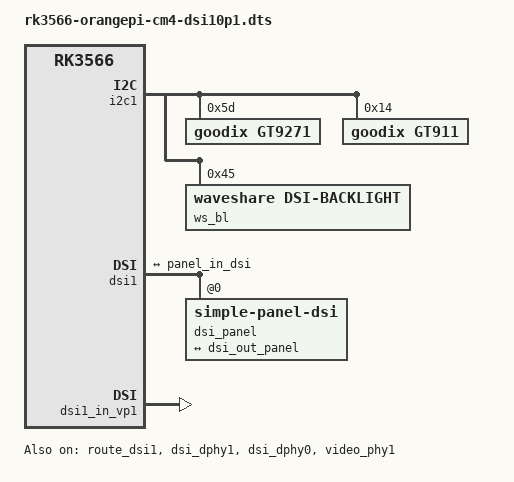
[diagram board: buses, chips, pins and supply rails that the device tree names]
// SPDX-License-Identifier: (GPL-2.0+ OR MIT)
/*
* Copyright (c) 2020 Rockchip Electronics Co., Ltd.
*
*/
/dts-v1/;

#include "rk3566-orangepi-cm4.dtsi"

&i2c1 {
    gt9271: gt9271@5d {
		status = "okay";
		compatible = "goodix,gt9271";
		reg = <0x5d>;
		pinctrl-names = "default";
	};

    gt911: gt911@14 {
		status = "okay";
		compatible = "goodix,gt911";
		reg = <0x14>;
    };

	ws_bl: ws-bl@45 {
		status = "okay";
		compatible = "waveshare,dsi-backlight";
		reg = <0x45>;
		default-brightness-level = <200>;
		max-brightness-level = <255>;
		min-brightness-level = <5>;
	};
};

&dsi1 {
    status = "okay";

    dsi_panel: panel@0 {
		status = "okay";
		compatible = "simple-panel-dsi";
		reg = <0>;

		//reset-gpios = <&gpio0 RK_PB5 GPIO_ACTIVE_LOW>;
		prepare-delay-ms = <120>;
		reset-delay-ms = <120>;
		init-delay-ms = <120>;
		disable-delay-ms = <120>;
		unprepare-delay-ms = <120>;

		dsi,flags = <(MIPI_DSI_MODE_VIDEO | MIPI_DSI_MODE_VIDEO_BURST | MIPI_DSI_MODE_LPM | MIPI_DSI_MODE_NO_EOT_PACKET )>;
		dsi,format = <MIPI_DSI_FMT_RGB888>;
		dsi,lanes  = <2>;
		//dsi,lanes  = <1>; // for 800x480

		// 10inch1
		width-mm = <216>;
		height-mm = <135>;

		// 10inch1
		panel-init-sequence = [
			15 00 02 E0 00
			15 00 02 E1 93
			15 00 02 E2 65
			15 00 02 E3 F8
			15 00 02 80 01
			15 00 02 E0 01
			15 00 02 00 00
			15 00 02 01 38
			15 00 02 03 10
			15 00 02 04 38
			15 00 02 0C 74
			15 00 02 17 00
			15 00 02 18 AF
			15 00 02 19 00
			15 00 02 1A 00
			15 00 02 1B AF
			15 00 02 1C 00
			15 00 02 35 26
			15 00 02 37 09
			15 00 02 38 04
			15 00 02 39 00
			15 00 02 3A 01
			15 00 02 3C 78
			15 00 02 3D FF
			15 00 02 3E FF
			15 00 02 3F 7F
			15 00 02 40 06
			15 00 02 41 A0
			15 00 02 42 81
			15 00 02 43 1E
			15 00 02 44 0D
			15 00 02 45 28
			15 00 02 55 02
			15 00 02 57 69
			15 00 02 59 0A
			15 00 02 5A 2A
			15 00 02 5B 17
			15 00 02 5D 7F
			15 00 02 5E 6A
			15 00 02 5F 5B
			15 00 02 60 4F
			15 00 02 61 4A
			15 00 02 62 3D
			15 00 02 63 41
			15 00 02 64 2A
			15 00 02 65 44
			15 00 02 66 43
			15 00 02 67 44
			15 00 02 68 62
			15 00 02 69 52
			15 00 02 6A 59
			15 00 02 6B 4C
			15 00 02 6C 48
			15 00 02 6D 3A
			15 00 02 6E 26
			15 00 02 6F 00
			15 00 02 70 7F
			15 00 02 71 6A
			15 00 02 72 5B
			15 00 02 73 4F
			15 00 02 74 4A
			15 00 02 75 3D
			15 00 02 76 41
			15 00 02 77 2A
			15 00 02 78 44
			15 00 02 79 43
			15 00 02 7A 44
			15 00 02 7B 62
			15 00 02 7C 52
			15 00 02 7D 59
			15 00 02 7E 4C
			15 00 02 7F 48
			15 00 02 80 3A
			15 00 02 81 26
			15 00 02 82 00
			15 00 02 E0 02
			15 00 02 00 42
			15 00 02 01 42
			15 00 02 02 40
			15 00 02 03 40
			15 00 02 04 5E
			15 00 02 05 5E
			15 00 02 06 5F
			15 00 02 07 5F
			15 00 02 08 5F
			15 00 02 09 57
			15 00 02 0A 57
			15 00 02 0B 77
			15 00 02 0C 77
			15 00 02 0D 47
			15 00 02 0E 47
			15 00 02 0F 45
			15 00 02 10 45
			15 00 02 11 4B
			15 00 02 12 4B
			15 00 02 13 49
			15 00 02 14 49
			15 00 02 15 5F
			15 00 02 16 41
			15 00 02 17 41
			15 00 02 18 40
			15 00 02 19 40
			15 00 02 1A 5E
			15 00 02 1B 5E
			15 00 02 1C 5F
			15 00 02 1D 5F
			15 00 02 1E 5F
			15 00 02 1F 57
			15 00 02 20 57
			15 00 02 21 77
			15 00 02 22 77
			15 00 02 23 46
			15 00 02 24 46
			15 00 02 25 44
			15 00 02 26 44
			15 00 02 27 4A
			15 00 02 28 4A
			15 00 02 29 48
			15 00 02 2A 48
			15 00 02 2B 5F
			15 00 02 2C 01
			15 00 02 2D 01
			15 00 02 2E 00
			15 00 02 2F 00
			15 00 02 30 1F
			15 00 02 31 1F
			15 00 02 32 1E
			15 00 02 33 1E
			15 00 02 34 1F
			15 00 02 35 17
			15 00 02 36 17
			15 00 02 37 37
			15 00 02 38 37
			15 00 02 39 08
			15 00 02 3A 08
			15 00 02 3B 0A
			15 00 02 3C 0A
			15 00 02 3D 04
			15 00 02 3E 04
			15 00 02 3F 06
			15 00 02 40 06
			15 00 02 41 1F
			15 00 02 42 02
			15 00 02 43 02
			15 00 02 44 00
			15 00 02 45 00
			15 00 02 46 1F
			15 00 02 47 1F
			15 00 02 48 1E
			15 00 02 49 1E
			15 00 02 4A 1F
			15 00 02 4B 17
			15 00 02 4C 17
			15 00 02 4D 37
			15 00 02 4E 37
			15 00 02 4F 09
			15 00 02 50 09
			15 00 02 51 0B
			15 00 02 52 0B
			15 00 02 53 05
			15 00 02 54 05
			15 00 02 55 07
			15 00 02 56 07
			15 00 02 57 1F
			15 00 02 58 40
			15 00 02 5B 30
			15 00 02 5C 00
			15 00 02 5D 34
			15 00 02 5E 05
			15 00 02 5F 02
			15 00 02 63 00
			15 00 02 64 6A
			15 00 02 67 73
			15 00 02 68 07
			15 00 02 69 08
			15 00 02 6A 6A
			15 00 02 6B 08
			15 00 02 6C 00
			15 00 02 6D 00
			15 00 02 6E 00
			15 00 02 6F 88
			15 00 02 75 FF
			15 00 02 77 DD
			15 00 02 78 2C
			15 00 02 79 15
			15 00 02 7A 17
			15 00 02 7D 14
			15 00 02 7E 82
			15 00 02 E0 04
			15 00 02 00 0E
			15 00 02 02 B3
			15 00 02 09 61
			15 00 02 0E 48
			15 00 02 E0 00
			15 00 02 E6 02
			15 00 02 E7 0C
			05 78 01 11
			05 00 01 E0
			05 05 01 29
		];

        disp_timings0: display-timings {
			native-mode = <&dsi_timing0>;

			// 10inch1
			dsi_timing0: timing0 {
				clock-frequency = <70000000>;//60fps
				//clock-frequency = <69907200>;

				hactive = <800>;
				vactive = <1280>;

				vsync-len = <4>;
				vback-porch = <10>;
				vfront-porch = <30>;

				hsync-len = <20>;
				hback-porch = <20>;
				hfront-porch = <40>;

				vsync-active = <0>;
				hsync-active = <0>;
				de-active = <0>;
				pixelclk-active = <0>;
			};
        };

        ports {
            #address-cells = <1>;
            #size-cells = <0>;

            port@0 {
                reg = <0>;
                panel_in_dsi: endpoint {
                    remote-endpoint = <&dsi_out_panel>;
                };
            };
        };
    };

    ports {
        #address-cells = <1>;
        #size-cells = <0>;

        port@1 {
            reg = <1>;
            dsi_out_panel: endpoint {
                remote-endpoint = <&panel_in_dsi>;
            };
        };
    };
};

&dsi1_in_vp1 {
    status = "okay";
};

&route_dsi1 {
    status = "okay";
    connect = <&vp1_out_dsi1>;
};

&dsi_dphy1 {
    status = "okay";
};

&dsi_dphy0 {
    status = "okay";
};

&video_phy1 {
	status = "okay";
};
